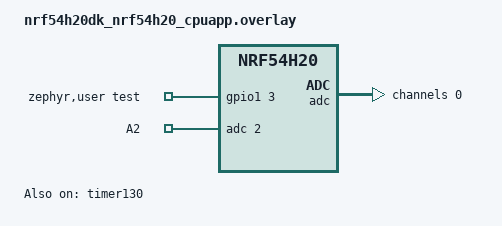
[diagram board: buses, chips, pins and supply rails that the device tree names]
/*
 * Copyright (c) 2025 Nordic Semiconductor ASA
 *
 * SPDX-License-Identifier: LicenseRef-Nordic-5-Clause
 */

/*
 * Required loopbacks:
 * P1.02 (AIN2) <-> P1.03
 */

/ {
	aliases {
		tst-timer = &timer130;
	};

	zephyr,user {
		test-gpios = <&gpio1 3 GPIO_ACTIVE_HIGH>;
		io-channels = <&adc 2>;
		io-channel-names = "A2";
	};
};

dut_adc: &adc {
	#address-cells = <1>;
	#size-cells = <0>;

	channel@0 {
		reg = <0>;
		zephyr,gain = "ADC_GAIN_1";
		zephyr,reference = "ADC_REF_INTERNAL";
		zephyr,acquisition-time = <ADC_ACQ_TIME_DEFAULT>;
		zephyr,input-positive = <NRF_SAADC_AIN2>;
	};
};

&gpio1 {
	status = "okay";
};

&timer130 {
	status = "okay";
};
